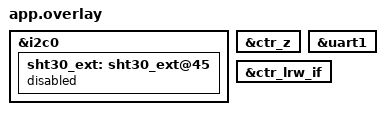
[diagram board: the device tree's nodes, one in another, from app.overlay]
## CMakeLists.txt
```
#
# Copyright (c) 2023 HARDWARIO a.s.
#
# SPDX-License-Identifier: LicenseRef-HARDWARIO-5-Clause
#

cmake_minimum_required(VERSION 3.20.0)

# Supported shields: ctr_lte ctr_x0_a ctr_s2 ctr_z ctr_ds18b20
set(SHIELD ctr_ds18b20 ctr_lte ctr_x0_a ctr_z)

find_package(Zephyr REQUIRED HINTS $ENV{ZEPHYR_BASE})
project(input)

target_sources(app PRIVATE src/app_backup.c)
target_sources(app PRIVATE src/app_cbor.c)
target_sources(app PRIVATE src/app_config.c)
target_sources(app PRIVATE src/app_data.c)
target_sources(app PRIVATE src/app_handler.c)
target_sources(app PRIVATE src/app_init.c)
target_sources(app PRIVATE src/app_power.c)
target_sources(app PRIVATE src/app_send.c)
target_sources(app PRIVATE src/app_sensor.c)
target_sources(app PRIVATE src/app_shell.c)
target_sources(app PRIVATE src/app_work.c)

target_sources(app PRIVATE src/main.c)
```

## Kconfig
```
mainmenu "CHESTER Input"

source "Kconfig.zephyr"
```

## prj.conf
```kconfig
#
# Copyright (c) 2023 HARDWARIO a.s.
#
# SPDX-License-Identifier: LicenseRef-HARDWARIO-5-Clause
#

CONFIG_ADC_SHELL=n
CONFIG_CTR_ACCEL=y
CONFIG_CTR_ADC=y
CONFIG_CTR_BATT=y
CONFIG_CTR_BLE=y
CONFIG_CTR_BUF=y
CONFIG_CTR_BUTTON=y
CONFIG_CTR_DEFAULTS=y
CONFIG_CTR_EDGE=y
CONFIG_CTR_INFO=y
CONFIG_CTR_LED=y
CONFIG_CTR_LOG=y
CONFIG_CTR_LTE_CLKSYNC=y
CONFIG_CTR_RTC=y
CONFIG_CTR_SHELL=y
CONFIG_CTR_THERM=y
CONFIG_CTR_WDOG=y
CONFIG_ENTROPY_GENERATOR=y
CONFIG_TINYCRYPT_SHA256=y
CONFIG_TINYCRYPT=y
CONFIG_ZCBOR_STOP_ON_ERROR=y
CONFIG_ZCBOR=y
```

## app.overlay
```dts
&i2c0 {
	sht30_ext: sht30_ext@45 {
		status = "disabled";
	};
};

&ctr_z {
	status = "okay";
};

&uart1 {
	status = "okay";
};

&ctr_lrw_if {
	status = "okay";
};
```

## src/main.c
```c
/*
 * Copyright (c) 2023 HARDWARIO a.s.
 *
 * SPDX-License-Identifier: LicenseRef-HARDWARIO-5-Clause
 */

#include "app_init.h"

/* CHESTER includes */
#include <chester/ctr_led.h>
#include <chester/ctr_wdog.h>

/* Zephyr includes */
#include <zephyr/kernel.h>
#include <zephyr/logging/log.h>

/* Standard includes */
#include <stdbool.h>

LOG_MODULE_REGISTER(main, LOG_LEVEL_DBG);

extern struct ctr_wdog_channel g_app_wdog_channel;

int main(void)
{
	int ret;

	LOG_INF("Build time: " __DATE__ " " __TIME__);

	ret = app_init();
	if (ret) {
		LOG_ERR("Call `app_init` failed: %d", ret);
		k_oops();
	}

	for (;;) {
		LOG_INF("Alive");

		ret = ctr_wdog_feed(&g_app_wdog_channel);
		if (ret) {
			LOG_ERR("Call `ctr_wdog_feed` failed: %d", ret);
			k_oops();
		}

		ctr_led_set(CTR_LED_CHANNEL_G, true);
		k_sleep(K_MSEC(30));
		ctr_led_set(CTR_LED_CHANNEL_G, false);

		k_sleep(K_SECONDS(5));
	}

	return 0;
}
```

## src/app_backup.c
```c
#include "app_backup.h"
#include "app_data.h"

/* CHESTER includes */
#include <chester/drivers/ctr_z.h>

/* Zephyr includes */
#include <zephyr/device.h>
#include <zephyr/devicetree.h>
#include <zephyr/kernel.h>
#include <zephyr/logging/log.h>

/* Standard includes */
#include <errno.h>
#include <math.h>

LOG_MODULE_REGISTER(app_backup, LOG_LEVEL_DBG);

#if defined(CONFIG_SHIELD_CTR_Z)

int app_backup_sample(void)
{
	int ret;

	static const struct device *dev = DEVICE_DT_GET(DT_NODELABEL(ctr_z));

	if (!device_is_ready(dev)) {
		LOG_ERR("Device not ready");
		ret = -ENODEV;
		goto error;
	}

	struct ctr_z_status status;
	ret = ctr_z_get_status(dev, &status);
	if (ret) {
		LOG_ERR("Call `ctr_z_get_status` failed: %d", ret);
		goto error;
	}

	LOG_INF("DC input connected: %d", status.dc_input_connected);

	uint16_t vdc;
	ret = ctr_z_get_vdc_mv(dev, &vdc);
	if (ret) {
		LOG_ERR("Call `ctr_z_get_vdc_mv` failed: %d", ret);
		goto error;
	}

	LOG_INF("Voltage DC input: %u mV", vdc);

	uint16_t vbat;
	ret = ctr_z_get_vbat_mv(dev, &vbat);
	if (ret) {
		LOG_ERR("Call `ctr_z_get_vbat_mv` failed: %d", ret);
		goto error;
	}

	LOG_INF("Voltage backup battery: %u mV", vbat);

	app_data_lock();
	g_app_data.backup.line_present = status.dc_input_connected;
	g_app_data.backup.line_voltage = vdc / 1000.f;
	g_app_data.backup.battery_voltage = vbat / 1000.f;
	app_data_unlock();

	return 0;

error:
	app_data_lock();
	g_app_data.backup.line_present = false;
	g_app_data.backup.line_voltage = NAN;
	g_app_data.backup.battery_voltage = NAN;
	app_data_unlock();

	return ret;
}

int app_backup_clear(void)
{
	app_data_lock();
	g_app_data.backup.event_count = 0;
	app_data_unlock();

	return 0;
}

#endif /* defined(CONFIG_SHIELD_CTR_Z) */
```

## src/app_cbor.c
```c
/*
 * Copyright (c) 2023 HARDWARIO a.s.
 *
 * SPDX-License-Identifier: LicenseRef-HARDWARIO-5-Clause
 */

#include "app_cbor.h"
#include "app_config.h"
#include "app_data.h"
#include "msg_key.h"

/* CHESTER includes */
#include <chester/ctr_ds18b20.h>
#include <chester/ctr_info.h>
#include <chester/ctr_rtc.h>

/* Zephyr includes */
#include <zephyr/kernel.h>
#include <zephyr/logging/log.h>

#include <zcbor_common.h>
#include <zcbor_encode.h>

/* Standard includes */
#include <errno.h>
#include <math.h>
#include <stdbool.h>
#include <stddef.h>
#include <stdint.h>
#include <stdlib.h>

LOG_MODULE_REGISTER(app_cbor, LOG_LEVEL_DBG);

#if defined(CONFIG_SHIELD_CTR_X0_A)

__unused static void put_sample_mul(zcbor_state_t *zs, struct app_data_aggreg *sample, float mul)
{
	if (isnan(sample->min)) {
		zcbor_nil_put(zs, NULL);
	} else {
		zcbor_int32_put(zs, sample->min * mul);
	}

	if (isnan(sample->max)) {
		zcbor_nil_put(zs, NULL);
	} else {
		zcbor_int32_put(zs, sample->max * mul);
	}

	if (isnan(sample->avg)) {
		zcbor_nil_put(zs, NULL);
	} else {
		zcbor_int32_put(zs, sample->avg * mul);
	}

	if (isnan(sample->mdn)) {
		zcbor_nil_put(zs, NULL);
	} else {
		zcbor_int32_put(zs, sample->mdn * mul);
	}
}

__unused static void put_sample(zcbor_state_t *zs, struct app_data_aggreg *sample)
{
	put_sample_mul(zs, sample, 1.f);
}

#endif /* defined(CONFIG_SHIELD_CTR_X0_A) */

static int encode(zcbor_state_t *zs)
{
	int ret;

	zs->constant_state->stop_on_error = true;

	zcbor_map_start_encode(zs, ZCBOR_VALUE_IS_INDEFINITE_LENGTH);

	zcbor_uint32_put(zs, MSG_KEY_MESSAGE);
	{
		zcbor_map_start_encode(zs, ZCBOR_VALUE_IS_INDEFINITE_LENGTH);

		zcbor_uint32_put(zs, MSG_KEY_VERSION);
		zcbor_uint32_put(zs, 1);

		static uint32_t sequence;
		zcbor_uint32_put(zs, MSG_KEY_SEQUENCE);
		zcbor_uint32_put(zs, sequence++);

		uint64_t timestamp;
		ret = ctr_rtc_get_ts(&timestamp);
		if (ret) {
			LOG_ERR("Call `ctr_rtc_get_ts` failed: %d", ret);
			return ret;
		}

		zcbor_uint32_put(zs, MSG_KEY_TIMESTAMP);
		zcbor_uint64_put(zs, timestamp);

		zcbor_map_end_encode(zs, ZCBOR_VALUE_IS_INDEFINITE_LENGTH);
	}

	zcbor_uint32_put(zs, MSG_KEY_ATTRIBUTE);
	{
		zcbor_map_start_encode(zs, ZCBOR_VALUE_IS_INDEFINITE_LENGTH);

		char *vendor_name;
		ctr_info_get_vendor_name(&vendor_name);

		zcbor_uint32_put(zs, MSG_KEY_VENDOR_NAME);
		zcbor_tstr_put_term(zs, vendor_name, CONFIG_ZCBOR_MAX_STR_LEN);

		char *product_name;
		ctr_info_get_product_name(&product_name);

		zcbor_uint32_put(zs, MSG_KEY_PRODUCT_NAME);
		zcbor_tstr_put_term(zs, product_name, CONFIG_ZCBOR_MAX_STR_LEN);

		char *hw_variant;
		ctr_info_get_hw_variant(&hw_variant);

		zcbor_uint32_put(zs, MSG_KEY_HW_VARIANT);
		zcbor_tstr_put_term(zs, hw_variant, CONFIG_ZCBOR_MAX_STR_LEN);

		char *hw_revision;
		ctr_info_get_hw_revision(&hw_revision);

		zcbor_uint32_put(zs, MSG_KEY_HW_REVISION);
		zcbor_tstr_put_term(zs, hw_revision, CONFIG_ZCBOR_MAX_STR_LEN);

		char *fw_name;
		ctr_info_get_fw_name(&fw_name);

		zcbor_uint32_put(zs, MSG_KEY_FW_NAME);
		zcbor_tstr_put_term(zs, fw_name, CONFIG_ZCBOR_MAX_STR_LEN);

		char *fw_version;
		ctr_info_get_fw_version(&fw_version);

		zcbor_uint32_put(zs, MSG_KEY_FW_VERSION);
		zcbor_tstr_put_term(zs, fw_version, CONFIG_ZCBOR_MAX_STR_LEN);

		char *serial_number;
		ctr_info_get_serial_number(&serial_number);

		zcbor_uint32_put(zs, MSG_KEY_SERIAL_NUMBER);
		zcbor_tstr_put_term(zs, serial_number, CONFIG_ZCBOR_MAX_STR_LEN);

		zcbor_map_end_encode(zs, ZCBOR_VALUE_IS_INDEFINITE_LENGTH);
	}

	zcbor_uint32_put(zs, MSG_KEY_SYSTEM);
	{
		zcbor_map_start_encode(zs, ZCBOR_VALUE_IS_INDEFINITE_LENGTH);

		zcbor_uint32_put(zs, MSG_KEY_UPTIME);
		zcbor_uint64_put(zs, k_uptime_get() / 1000);

		zcbor_uint32_put(zs, MSG_KEY_VOLTAGE_REST);
		if (isnan(g_app_data.system_voltage_rest)) {
			zcbor_nil_put(zs, NULL);
		} else {
			zcbor_uint32_put(zs, g_app_data.system_voltage_rest);
		}

		zcbor_uint32_put(zs, MSG_KEY_VOLTAGE_LOAD);
		if (isnan(g_app_data.system_voltage_load)) {
			zcbor_nil_put(zs, NULL);
		} else {
			zcbor_uint32_put(zs, g_app_data.system_voltage_load);
		}

		zcbor_uint32_put(zs, MSG_KEY_CURRENT_LOAD);
		if (isnan(g_app_data.system_current_load)) {
			zcbor_nil_put(zs, NULL);
		} else {
			zcbor_uint32_put(zs, g_app_data.system_current_load);
		}

		zcbor_map_end_encode(zs, ZCBOR_VALUE_IS_INDEFINITE_LENGTH);
	}

#if defined(CONFIG_SHIELD_CTR_Z)
	zcbor_uint32_put(zs, MSG_KEY_BACKUP);
	{
		zcbor_map_start_encode(zs, ZCBOR_VALUE_IS_INDEFINITE_LENGTH);

		zcbor_uint32_put(zs, MSG_KEY_LINE_VOLTAGE);
		if (isnan(g_app_data.backup.line_voltage)) {
			zcbor_nil_put(zs, NULL);
		} else {
			zcbor_int32_put(zs, g_app_data.backup.line_voltage * 1000.f);
		}

		zcbor_uint32_put(zs, MSG_KEY_BATT_VOLTAGE);
		if (isnan(g_app_data.backup.battery_voltage)) {
			zcbor_nil_put(zs, NULL);
		} else {
			zcbor_int32_put(zs, g_app_data.backup.battery_voltage * 1000.f);
		}

		zcbor_uint32_put(zs, MSG_KEY_BACKUP_STATE);
		zcbor_uint32_put(zs, g_app_data.backup.line_present ? 1 : 0);

		if (g_app_data.backup.event_count) {
			int64_t timestamp_abs = g_app_data.backup.events[0].timestamp;

			zcbor_uint32_put(zs, MSG_KEY_BACKUP_EVENTS);
			{
				zcbor_list_start_encode(zs, ZCBOR_VALUE_IS_INDEFINITE_LENGTH);

				/* TSO absolute timestamp */
				zcbor_int64_put(zs, timestamp_abs);

				for (int i = 0; i < g_app_data.backup.event_count; i++) {
					/* TSO offset timestamp */
					zcbor_int64_put(zs, g_app_data.backup.events[i].timestamp -
								    timestamp_abs);
					zcbor_uint32_put(
						zs, g_app_data.backup.events[i].connected ? 1 : 0);
				}

				zcbor_list_end_encode(zs, ZCBOR_VALUE_IS_INDEFINITE_LENGTH);
			}
		} else {
			zcbor_uint32_put(zs, MSG_KEY_BACKUP_EVENTS);
			{
				zcbor_list_start_encode(zs, ZCBOR_VALUE_IS_INDEFINITE_LENGTH);
				zcbor_list_end_encode(zs, ZCBOR_VALUE_IS_INDEFINITE_LENGTH);
			}
		}

		zcbor_map_end_encode(zs, ZCBOR_VALUE_IS_INDEFINITE_LENGTH);
	}
#endif /* defined(CONFIG_SHIELD_CTR_Z) */

	zcbor_uint32_put(zs, MSG_KEY_NETWORK);
	{
		zcbor_map_start_encode(zs, ZCBOR_VALUE_IS_INDEFINITE_LENGTH);

		uint64_t imei;
		ret = ctr_lte_get_imei(&imei);
		if (ret) {
			LOG_ERR("Call `ctr_lte_get_imei` failed: %d", ret);
			return ret;
		}

		zcbor_uint32_put(zs, MSG_KEY_IMEI);
		zcbor_uint64_put(zs, imei);

		uint64_t imsi;
		ret = ctr_lte_get_imsi(&imsi);
		if (ret) {
			LOG_ERR("Call `ctr_lte_get_imsi` failed: %d", ret);
			return ret;
		}

		zcbor_uint32_put(zs, MSG_KEY_IMSI);
		zcbor_uint64_put(zs, imsi);

		zcbor_uint32_put(zs, MSG_KEY_PARAMETER);
		{
			zcbor_map_start_encode(zs, ZCBOR_VALUE_IS_INDEFINITE_LENGTH);

			k_mutex_lock(&g_app_data_lte_eval_mut, K_FOREVER);

			zcbor_uint32_put(zs, MSG_KEY_EEST);
			if (g_app_data_lte_eval_valid) {
				zcbor_int32_put(zs, g_app_data_lte_eval.eest);
			} else {
				zcbor_nil_put(zs, NULL);
			}

			zcbor_uint32_put(zs, MSG_KEY_ECL);
			if (g_app_data_lte_eval_valid) {
				zcbor_int32_put(zs, g_app_data_lte_eval.ecl);
			} else {
				zcbor_nil_put(zs, NULL);
			}

			zcbor_uint32_put(zs, MSG_KEY_RSRP);
			if (g_app_data_lte_eval_valid) {
				zcbor_int32_put(zs, g_app_data_lte_eval.rsrp);
			} else {
				zcbor_nil_put(zs, NULL);
			}

			zcbor_uint32_put(zs, MSG_KEY_RSRQ);
			if (g_app_data_lte_eval_valid) {
				zcbor_int32_put(zs, g_app_data_lte_eval.rsrq);
			} else {
				zcbor_nil_put(zs, NULL);
			}

			zcbor_uint32_put(zs, MSG_KEY_SNR);
			if (g_app_data_lte_eval_valid) {
				zcbor_int32_put(zs, g_app_data_lte_eval.snr);
			} else {
				zcbor_nil_put(zs, NULL);
			}

			zcbor_uint32_put(zs, MSG_KEY_PLMN);
			if (g_app_data_lte_eval_valid) {
				zcbor_int32_put(zs, g_app_data_lte_eval.plmn);
			} else {
				zcbor_nil_put(zs, NULL);
			}

			zcbor_uint32_put(zs, MSG_KEY_CID);
			if (g_app_data_lte_eval_valid) {
				zcbor_int32_put(zs, g_app_data_lte_eval.cid);
			} else {
				zcbor_nil_put(zs, NULL);
			}

			zcbor_uint32_put(zs, MSG_KEY_BAND);
			if (g_app_data_lte_eval_valid) {
				zcbor_int32_put(zs, g_app_data_lte_eval.band);
			} else {
				zcbor_nil_put(zs, NULL);
			}

			zcbor_uint32_put(zs, MSG_KEY_EARFCN);
			if (g_app_data_lte_eval_valid) {
				zcbor_int32_put(zs, g_app_data_lte_eval.earfcn);
			} else {
				zcbor_nil_put(zs, NULL);
			}

			g_app_data_lte_eval_valid = false;

			k_mutex_unlock(&g_app_data_lte_eval_mut);

			zcbor_map_end_encode(zs, ZCBOR_VALUE_IS_INDEFINITE_LENGTH);
		}

		zcbor_map_end_encode(zs, ZCBOR_VALUE_IS_INDEFINITE_LENGTH);
	}

	zcbor_uint32_put(zs, MSG_KEY_THERMOMETER);
	{
		zcbor_map_start_encode(zs, ZCBOR_VALUE_IS_INDEFINITE_LENGTH);

		zcbor_uint32_put(zs, MSG_KEY_TEMPERATURE);
		if (isnan(g_app_data.therm_temperature)) {
			zcbor_nil_put(zs, NULL);
		} else {
			zcbor_int32_put(zs, g_app_data.therm_temperature * 100.f);
		}

		zcbor_map_end_encode(zs, ZCBOR_VALUE_IS_INDEFINITE_LENGTH);
	}

	zcbor_uint32_put(zs, MSG_KEY_ACCELEROMETER);
	{
		zcbor_map_start_encode(zs, ZCBOR_VALUE_IS_INDEFINITE_LENGTH);

		zcbor_uint32_put(zs, MSG_KEY_ACCELERATION_X);
		if (isnan(g_app_data.accel_acceleration_x)) {
			zcbor_nil_put(zs, NULL);
		} else {
			zcbor_int32_put(zs, g_app_data.accel_acceleration_x * 1000.f);
		}

		zcbor_uint32_put(zs, MSG_KEY_ACCELERATION_Y);
		if (isnan(g_app_data.accel_acceleration_y)) {
			zcbor_nil_put(zs, NULL);
		} else {
			zcbor_int32_put(zs, g_app_data.accel_acceleration_y * 1000.f);
		}

		zcbor_uint32_put(zs, MSG_KEY_ACCELERATION_Z);
		if (isnan(g_app_data.accel_acceleration_z)) {
			zcbor_nil_put(zs, NULL);
		} else {
			zcbor_int32_put(zs, g_app_data.accel_acceleration_z * 1000.f);
		}

		zcbor_uint32_put(zs, MSG_KEY_ORIENTATION);
		if (g_app_data.accel_orientation == INT_MAX) {
			zcbor_nil_put(zs, NULL);
		} else {
			zcbor_uint32_put(zs, g_app_data.accel_orientation);
		}

		zcbor_map_end_encode(zs, ZCBOR_VALUE_IS_INDEFINITE_LENGTH);
	}

#if defined(CONFIG_SHIELD_CTR_X0_A)
	zcbor_uint32_put(zs, MSG_KEY_TRIGGER);
	{
		zcbor_map_start_encode(zs, ZCBOR_VALUE_IS_INDEFINITE_LENGTH);

		zcbor_uint32_put(zs, MSG_KEY_TRIGGER_STATE);
		zcbor_uint32_put(zs, g_app_data.trigger.trigger_active ? 1 : 0);

		if (g_app_data.trigger.event_count) {

			int64_t timestamp_abs = g_app_data.trigger.events[0].timestamp;

			zcbor_uint32_put(zs, MSG_KEY_TRIGGER_EVENTS);
			{
				zcbor_list_start_encode(zs, ZCBOR_VALUE_IS_INDEFINITE_LENGTH);

				/* TSO absolute timestamp */
				zcbor_int64_put(zs, timestamp_abs);

				for (int i = 0; i < g_app_data.trigger.event_count; i++) {
					/* TSO offset timestamp */
					zcbor_int64_put(zs, g_app_data.trigger.events[i].timestamp -
								    timestamp_abs);
					zcbor_uint32_put(
						zs, g_app_data.trigger.events[i].is_active ? 1 : 0);
				}

				zcbor_list_end_encode(zs, ZCBOR_VALUE_IS_INDEFINITE_LENGTH);
			}
		} else {
			zcbor_uint32_put(zs, MSG_KEY_TRIGGER_EVENTS);
			{
				zcbor_list_start_encode(zs, ZCBOR_VALUE_IS_INDEFINITE_LENGTH);
				zcbor_list_end_encode(zs, ZCBOR_VALUE_IS_INDEFINITE_LENGTH);
			}
		}
		zcbor_map_end_encode(zs, ZCBOR_VALUE_IS_INDEFINITE_LENGTH);
	}

	zcbor_uint32_put(zs, MSG_KEY_COUNTER);
	{
		zcbor_map_start_encode(zs, ZCBOR_VALUE_IS_INDEFINITE_LENGTH);

		zcbor_uint32_put(zs, MSG_KEY_VALUE);
		zcbor_uint64_put(zs, g_app_data.counter.value);

		zcbor_uint32_put(zs, MSG_KEY_DELTA);
		zcbor_uint64_put(zs, g_app_data.counter.delta);

		g_app_data.counter.delta = 0;

		zcbor_uint32_put(zs, MSG_KEY_MEASUREMENTS_VAL);
		{
			zcbor_list_start_encode(zs, ZCBOR_VALUE_IS_INDEFINITE_LENGTH);

			zcbor_uint64_put(zs, g_app_data.counter.timestamp);
			zcbor_uint32_put(zs, g_app_config.counter_interval_aggreg);

			for (int i = 0; i < g_app_data.counter.measurement_count; i++) {
				zcbor_uint64_put(zs, g_app_data.counter.measurements[i].value);
			}

			zcbor_list_end_encode(zs, ZCBOR_VALUE_IS_INDEFINITE_LENGTH);
		}
		zcbor_map_end_encode(zs, ZCBOR_VALUE_IS_INDEFINITE_LENGTH);
	}

	zcbor_uint32_put(zs, MSG_KEY_VOLTAGE);
	{
		zcbor_map_start_encode(zs, ZCBOR_VALUE_IS_INDEFINITE_LENGTH);

		zcbor_uint32_put(zs, MSG_KEY_MEASUREMENTS_DIV);
		{
			zcbor_list_start_encode(zs, ZCBOR_VALUE_IS_INDEFINITE_LENGTH);

			zcbor_uint64_put(zs, g_app_data.voltage.timestamp);
			zcbor_uint32_put(zs, g_app_config.analog_interval_aggreg);

			for (int i = 0; i < g_app_data.voltage.measurement_count; i++) {
				put_sample_mul(zs, &g_app_data.voltage.measurements[i], 100.f);
			}

			zcbor_list_end_encode(zs, ZCBOR_VALUE_IS_INDEFINITE_LENGTH);
		}
		zcbor_map_end_encode(zs, ZCBOR_VALUE_IS_INDEFINITE_LENGTH);
	}

	zcbor_uint32_put(zs, MSG_KEY_CURRENT);
	{
		zcbor_map_start_encode(zs, ZCBOR_VALUE_IS_INDEFINITE_LENGTH);

		zcbor_uint32_put(zs, MSG_KEY_MEASUREMENTS_DIV);
		{
			zcbor_list_start_encode(zs, ZCBOR_VALUE_IS_INDEFINITE_LENGTH);

			zcbor_uint64_put(zs, g_app_data.current.timestamp);
			zcbor_uint32_put(zs, g_app_config.analog_interval_aggreg);

			for (int i = 0; i < g_app_data.current.measurement_count; i++) {
				put_sample_mul(zs, &g_app_data.current.measurements[i], 100.f);
			}

			zcbor_list_end_encode(zs, ZCBOR_VALUE_IS_INDEFINITE_LENGTH);
		}
		zcbor_map_end_encode(zs, ZCBOR_VALUE_IS_INDEFINITE_LENGTH);
	}
#endif /* defined(CONFIG_SHIELD_CTR_X0_A) */

#if defined(CONFIG_SHIELD_CTR_S2)
	zcbor_uint32_put(zs, MSG_KEY_HYGROMETER);
	{
		zcbor_map_start_encode(zs, ZCBOR_VALUE_IS_INDEFINITE_LENGTH);

		zcbor_uint32_put(zs, MSG_KEY_TEMPERATURE);
		{
			zcbor_map_start_encode(zs, ZCBOR_VALUE_IS_INDEFINITE_LENGTH);

			zcbor_uint32_put(zs, MSG_KEY_MEASUREMENTS_DIV);
			{
				zcbor_list_start_encode(zs, ZCBOR_VALUE_IS_INDEFINITE_LENGTH);

				zcbor_uint64_put(zs, g_app_data.hygro.timestamp);
				zcbor_uint32_put(zs, g_app_config.hygro_interval_aggreg);

				for (int i = 0; i < g_app_data.hygro.measurement_count; i++) {
					put_sample_mul(
						zs, &g_app_data.hygro.measurements[i].temperature,
						100.f);
				}

				zcbor_list_end_encode(zs, ZCBOR_VALUE_IS_INDEFINITE_LENGTH);
			}
			zcbor_map_end_encode(zs, ZCBOR_VALUE_IS_INDEFINITE_LENGTH);
		}

		zcbor_uint32_put(zs, MSG_KEY_HUMIDITY);
		{
			zcbor_map_start_encode(zs, ZCBOR_VALUE_IS_INDEFINITE_LENGTH);

			zcbor_uint32_put(zs, MSG_KEY_MEASUREMENTS_DIV);
			{
				zcbor_list_start_encode(zs, ZCBOR_VALUE_IS_INDEFINITE_LENGTH);

				zcbor_uint64_put(zs, g_app_data.hygro.timestamp);
				zcbor_uint32_put(zs, g_app_config.hygro_interval_aggreg);

				for (int i = 0; i < g_app_data.hygro.measurement_count; i++) {
					put_sample_mul(zs,
						       &g_app_data.hygro.measurements[i].humidity,
						       100.f);
				}

				zcbor_list_end_encode(zs, ZCBOR_VALUE_IS_INDEFINITE_LENGTH);
			}
			zcbor_map_end_encode(zs, ZCBOR_VALUE_IS_INDEFINITE_LENGTH);
		}

		zcbor_map_end_encode(zs, ZCBOR_VALUE_IS_INDEFINITE_LENGTH);
	}
#endif /* defined(CONFIG_SHIELD_CTR_S2) */

#if defined(CONFIG_SHIELD_CTR_DS18B20)
	if (ctr_ds18b20_get_count()) {
		zcbor_uint32_put(zs, MSG_KEY_W1_THERMOMETERS);
		{
			zcbor_list_start_encode(zs, ZCBOR_VALUE_IS_INDEFINITE_LENGTH);
			for (int i = 0; i < APP_DATA_W1_THERM_COUNT; i++) {
				struct app_data_w1_therm_sensor *sensor =
					&g_app_data.w1_therm.sensor[i];

				if (!sensor->serial_number) {
					continue;
				}

				zcbor_map_start_encode(zs, ZCBOR_VALUE_IS_INDEFINITE_LENGTH);

				zcbor_uint32_put(zs, MSG_KEY_SERIAL_NUMBER);
				zcbor_uint64_put(zs, sensor->serial_number);

				zcbor_uint32_put(zs, MSG_KEY_MEASUREMENTS_DIV);
				{
					zcbor_list_start_encode(zs,
								ZCBOR_VALUE_IS_INDEFINITE_LENGTH);

					zcbor_uint64_put(zs, g_app_data.w1_therm.timestamp);
					zcbor_uint32_put(zs, g_app_config.w1_therm_interval_aggreg);

					for (int j = 0; j < sensor->measurement_count; j++) {
						put_sample_mul(zs,
							       &sensor->measurements[j].temperature,
							       100.f);
					}

					zcbor_list_end_encode(zs, ZCBOR_VALUE_IS_INDEFINITE_LENGTH);
				}

				zcbor_map_end_encode(zs, ZCBOR_VALUE_IS_INDEFINITE_LENGTH);
			}
			zcbor_list_end_encode(zs, ZCBOR_VALUE_IS_INDEFINITE_LENGTH);
		}
	}
#endif /* defined(CONFIG_SHIELD_CTR_DS18B20) */

	zcbor_map_end_encode(zs, ZCBOR_VALUE_IS_INDEFINITE_LENGTH);

	if (!zcbor_check_error(zs)) {
		LOG_ERR("Encoding failed: %d", zcbor_pop_error(zs));
		return -EFAULT;
	}

	return 0;
}

int app_cbor_encode(zcbor_state_t *zs)
{
	int ret;

	app_data_lock();

	ret = encode(zs);
	if (ret) {
		LOG_ERR("Call `encode` failed: %d", ret);
		app_data_unlock();
		return ret;
	}

	app_data_unlock();

	return 0;
}
```

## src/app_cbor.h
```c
#ifndef APP_CBOR_H_
#define APP_CBOR_H_

/* Zephyr includes */
#include <zephyr/zephyr.h>

#include <zcbor_common.h>

#ifdef __cplusplus
extern "C" {
#endif

int app_cbor_encode(zcbor_state_t *zs);

#ifdef __cplusplus
}
#endif

#endif /* APP_CBOR_H_ */
```

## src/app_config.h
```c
/*
 * Copyright (c) 2023 HARDWARIO a.s.
 *
 * SPDX-License-Identifier: LicenseRef-HARDWARIO-5-Clause
 */

#ifndef APP_CONFIG_H_
#define APP_CONFIG_H_

/* Zephyr includes */
#include <zephyr/shell/shell.h>

/* Standard includes */
#include <stddef.h>

#ifdef __cplusplus
extern "C" {
#endif

#if defined(CONFIG_SHIELD_CTR_X0_A)
enum app_config_input_type {
	APP_CONFIG_INPUT_TYPE_NPN = 0,
	APP_CONFIG_INPUT_TYPE_PNP = 1,
};
#endif /* defined(CONFIG_SHIELD_CTR_X0_A) */

struct app_config {
	int interval_report;

#if defined(CONFIG_SHIELD_CTR_X0_A) || defined(CONFIG_SHIELD_CTR_Z)
	int event_report_delay;
	int event_report_rate;
#endif /* defined(CONFIG_SHIELD_CTR_X0_A) || defined(CONFIG_SHIELD_CTR_Z) */

#if defined(CONFIG_SHIELD_CTR_Z)
	bool backup_report_connected;
	bool backup_report_disconnected;
#endif /* defined(CONFIG_SHIELD_CTR_Z) */

#if defined(CONFIG_SHIELD_CTR_X0_A)
	enum app_config_input_type trigger_input_type;
	int trigger_duration_active;
	int trigger_duration_inactive;
	int trigger_cooldown_time;
	bool trigger_report_active;
	bool trigger_report_inactive;

	int counter_interval_aggreg;
	enum app_config_input_type counter_input_type;
	int counter_duration_active;
	int counter_duration_inactive;
	int counter_cooldown_time;
	int analog_interval_sample;
	int analog_interval_aggreg;
#endif /* defined(CONFIG_SHIELD_CTR_X0_A) */

#if defined(CONFIG_SHIELD_CTR_S2)
	int hygro_interval_sample;
	int hygro_interval_aggreg;
#endif /* defined(CONFIG_SHIELD_CTR_S2) */
};

extern struct app_config g_app_config;

int app_config_cmd_config_show(const struct shell *shell, size_t argc, char **argv);
int app_config_cmd_config_interval_report(const struct shell *shell, size_t argc, char **argv);

#if defined(CONFIG_SHIELD_CTR_X0_A) || defined(CONFIG_SHIELD_CTR_Z)
int app_config_cmd_config_event_report_delay(const struct shell *shell, size_t argc, char **argv);
int app_config_cmd_config_event_report_rate(const struct shell *shell, size_t argc, char **argv);
#endif /* defined(CONFIG_SHIELD_CTR_X0_A) || defined(CONFIG_SHIELD_CTR_Z) */

#if defined(CONFIG_SHIELD_CTR_Z)
int app_config_cmd_config_backup_report_connected(const struct shell *shell, size_t argc,
						  char **argv);
int app_config_cmd_config_backup_report_disconnected(const struct shell *shell, size_t argc,
						     char **argv);
#endif /* defined(CONFIG_SHIELD_CTR_Z) */

#if defined(CONFIG_SHIELD_CTR_X0_A)
int app_config_cmd_config_trigger_input_type(const struct shell *shell, size_t argc, char **argv);
int app_config_cmd_config_trigger_duration_active(const struct shell *shell, size_t argc,
						  char **argv);
int app_config_cmd_config_trigger_duration_inactive(const struct shell *shell, size_t argc,
						    char **argv);
int app_config_cmd_config_trigger_cooldown_time(const struct shell *shell, size_t argc,
						char **argv);
int app_config_cmd_config_trigger_report_active(const struct shell *shell, size_t argc,
						char **argv);
int app_config_cmd_config_trigger_report_inactive(const struct shell *shell, size_t argc,
						  char **argv);

int app_config_cmd_config_counter_interval_aggreg(const struct shell *shell, size_t argc,
						  char **argv);
int app_config_cmd_config_counter_input_type(const struct shell *shell, size_t argc, char **argv);
int app_config_cmd_config_counter_duration_active(const struct shell *shell, size_t argc,
						  char **argv);
int app_config_cmd_config_counter_duration_inactive(const struct shell *shell, size_t argc,
						    char **argv);
int app_config_cmd_config_counter_cooldown_time(const struct shell *shell, size_t argc,
						char **argv);
int app_config_cmd_config_analog_interval_sample(const struct shell *shell, size_t argc,
						 char **argv);
int app_config_cmd_config_analog_interval_aggreg(const struct shell *shell, size_t argc,
						 char **argv);
#endif /* defined(CONFIG_SHIELD_CTR_X0_A) */

#if defined(CONFIG_SHIELD_CTR_S2)
int app_config_cmd_config_hygro_interval_sample(const struct shell *shell, size_t argc,
						char **argv);
int app_config_cmd_config_hygro_interval_aggreg(const struct shell *shell, size_t argc,
						char **argv);
#endif /* defined(CONFIG_SHIELD_CTR_S2) */
#ifdef __cplusplus
}
#endif

#endif /* APP_CONFIG_H_ */
```

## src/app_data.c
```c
/*
 * Copyright (c) 2023 HARDWARIO a.s.
 *
 * SPDX-License-Identifier: LicenseRef-HARDWARIO-5-Clause
 */

#include "app_data.h"
#include "msg_key.h"

/* CHESTER includes */
#include <chester/ctr_lte.h>

/* Zephyr includes */
#include <zephyr/kernel.h>

/* Standard includes */
#include <limits.h>
#include <math.h>

struct app_data g_app_data = {
	.system_voltage_rest = NAN,
	.system_voltage_load = NAN,
	.system_current_load = NAN,
	.accel_acceleration_x = NAN,
	.accel_acceleration_y = NAN,
	.accel_acceleration_z = NAN,
	.accel_orientation = INT_MAX,
	.therm_temperature = NAN,
};

static K_MUTEX_DEFINE(m_lock);

void app_data_lock(void)
{
	k_mutex_lock(&m_lock, K_FOREVER);
}

void app_data_unlock(void)
{
	k_mutex_unlock(&m_lock);
}

K_MUTEX_DEFINE(g_app_data_lte_eval_mut);
bool g_app_data_lte_eval_valid;
struct ctr_lte_eval g_app_data_lte_eval;
```

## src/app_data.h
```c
/*
 * Copyright (c) 2023 HARDWARIO a.s.
 *
 * SPDX-License-Identifier: LicenseRef-HARDWARIO-5-Clause
 */

#ifndef APP_DATA_H_
#define APP_DATA_H_

/* CHESTER includes */
#include <chester/ctr_edge.h>
#include <chester/ctr_lte.h>

/* Standard includes */
#include <stdbool.h>
#include <stdint.h>

/* TODO Delete */
#include <zephyr/kernel.h>

#define APP_DATA_ANALOG_MAX_SAMPLES	 32
#define APP_DATA_ANALOG_MAX_MEASUREMENTS 32

#define APP_DATA_COUNTER_MAX_MEASUREMENTS 32

#define APP_DATA_MAX_TRIGGER_EVENTS 32
#define APP_DATA_MAX_BACKUP_EVENTS  32

#define APP_DATA_HYGRO_MAX_SAMPLES	32
#define APP_DATA_HYGRO_MAX_MEASUREMENTS 32

#if defined(CONFIG_SHIELD_CTR_DS18B20)
#define APP_DATA_W1_THERM_COUNT	      10
#define APP_DATA_W1_THERM_MAX_SAMPLES 128
#define APP_DATA_W1_THERM_MAX_MEASUREMENTS  32
#endif /* defined(CONFIG_SHIELD_CTR_DS18B20) */

#ifdef __cplusplus
extern "C" {
#endif

struct app_data_aggreg {
	float min;
	float max;
	float avg;
	float mdn;
};

#if defined(CONFIG_SHIELD_CTR_Z)

struct app_data_backup_event {
	int64_t timestamp;
	bool connected;
};

struct app_data_backup {
	float line_voltage;
	float battery_voltage;
	bool line_present;
	int event_count;
	struct app_data_backup_event events[APP_DATA_MAX_BACKUP_EVENTS];
};

#endif /* defined(CONFIG_SHIELD_CTR_Z) */

#if defined(CONFIG_SHIELD_CTR_X0_A)

struct app_data_trigger_event {
	int64_t timestamp;
	bool is_active;
};

struct app_data_trigger {
	bool trigger_active;
	int event_count;
	struct app_data_trigger_event events[APP_DATA_MAX_TRIGGER_EVENTS];
};

struct app_data_counter_measurement {
	uint64_t value;
};

struct app_data_counter {
	int64_t timestamp;
	uint64_t value;
	uint64_t delta;
	int measurement_count;
	struct app_data_counter_measurement measurements[APP_DATA_COUNTER_MAX_MEASUREMENTS];
};

struct app_data_analog {
	int64_t timestamp;
	int sample_count;
	float samples[APP_DATA_ANALOG_MAX_SAMPLES];
	int measurement_count;
	struct app_data_aggreg measurements[APP_DATA_ANALOG_MAX_MEASUREMENTS];
};

#endif /* defined(CONFIG_SHIELD_CTR_X0_A) */

#if defined(CONFIG_SHIELD_CTR_S2)

struct app_data_hygro_measurement {
	struct app_data_aggreg temperature;
	struct app_data_aggreg humidity;
};

struct app_data_hygro {
	int64_t timestamp;
	int sample_count;
	float samples_temperature[APP_DATA_HYGRO_MAX_SAMPLES];
	float samples_humidity[APP_DATA_HYGRO_MAX_SAMPLES];
	int measurement_count;
	struct app_data_hygro_measurement measurements[APP_DATA_HYGRO_MAX_MEASUREMENTS];
};

#endif /* defined(CONFIG_SHIELD_CTR_S2) */

#if defined(CONFIG_SHIELD_CTR_DS18B20)
struct app_data_w1_therm_measurement {
	struct app_data_aggreg temperature;
};

struct app_data_w1_therm_sensor {
	uint64_t serial_number;

	float last_sample_temperature;

	int sample_count;
	float samples_temperature[APP_DATA_W1_THERM_MAX_SAMPLES];

	int measurement_count;
	struct app_data_w1_therm_measurement measurements[APP_DATA_W1_THERM_MAX_MEASUREMENTS];
};

struct app_data_w1_therm {
	struct app_data_w1_therm_sensor sensor[APP_DATA_W1_THERM_COUNT];

	int64_t timestamp;
	atomic_t sample;
	atomic_t aggreg;
};
#endif /* defined(CONFIG_SHIELD_CTR_DS18B20) */

struct app_data {
	float system_voltage_rest;
	float system_voltage_load;
	float system_current_load;
	float therm_temperature;
	float accel_acceleration_x;
	float accel_acceleration_y;
	float accel_acceleration_z;
	int accel_orientation;

#if defined(CONFIG_SHIELD_CTR_Z)
	struct app_data_backup backup;
#endif /* defined(CONFIG_SHIELD_CTR_Z) */

#if defined(CONFIG_SHIELD_CTR_X0_A)
	struct app_data_counter counter;
	struct app_data_trigger trigger;
	struct app_data_analog voltage;
	struct app_data_analog current;
#endif /* defined(CONFIG_SHIELD_CTR_X0_A) */

#if defined(CONFIG_SHIELD_CTR_S2)
	struct app_data_hygro hygro;
#endif /* defined(CONFIG_SHIELD_CTR_S2) */

#if defined(CONFIG_SHIELD_CTR_DS18B20)
	struct app_data_w1_therm w1_therm;
#endif /* defined(CONFIG_SHIELD_CTR_DS18B20) */
};

extern struct app_data g_app_data;

/* TODO Delete */
extern struct k_mutex g_app_data_lte_eval_mut;
extern bool g_app_data_lte_eval_valid;
extern struct ctr_lte_eval g_app_data_lte_eval;

void app_data_lock(void);
void app_data_unlock(void);

#ifdef __cplusplus
}
#endif

#endif /* APP_DATA_H_ */
```

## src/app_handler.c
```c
/*
 * Copyright (c) 2023 HARDWARIO a.s.
 *
 * SPDX-License-Identifier: LicenseRef-HARDWARIO-5-Clause
 */

#include "app_config.h"
#include "app_data.h"
#include "app_handler.h"
#include "app_init.h"
#include "app_work.h"

/* CHESTER includes */
#include <chester/ctr_lte.h>
#include <chester/ctr_rtc.h>
#include <chester/drivers/ctr_z.h>

/* Zephyr includes */
#include <zephyr/kernel.h>
#include <zephyr/logging/log.h>

/* Standard includes */
#include <inttypes.h>
#include <math.h>
#include <stdbool.h>
#include <stddef.h>

LOG_MODULE_REGISTER(app_handler, LOG_LEVEL_DBG);

static atomic_t m_report_rate_hourly_counter = 0;
static atomic_t m_report_rate_timer_is_active = false;
static atomic_t m_report_delay_timer_is_active = false;

#if defined(CONFIG_SHIELD_CTR_LTE)

static void start(void)
{
	int ret;

	ret = ctr_lte_start(NULL);
	if (ret) {
		LOG_ERR("Call `ctr_lte_start` failed: %d", ret);
		k_oops();
	}
}

static void attach(void)
{
	int ret;

	ret = ctr_lte_attach(NULL);
	if (ret) {
		LOG_ERR("Call `ctr_lte_attach` failed: %d", ret);
		k_oops();
	}
}

void app_handler_lte(enum ctr_lte_event event, union ctr_lte_event_data *data, void *param)
{
	switch (event) {
	case CTR_LTE_EVENT_FAILURE:
		LOG_ERR("Event `CTR_LTE_EVENT_FAILURE`");
		start();
		break;

	case CTR_LTE_EVENT_START_OK:
		LOG_INF("Event `CTR_LTE_EVENT_START_OK`");
		attach();
		break;

	case CTR_LTE_EVENT_START_ERR:
		LOG_ERR("Event `CTR_LTE_EVENT_START_ERR`");
		start();
		break;

	case CTR_LTE_EVENT_ATTACH_OK:
		LOG_INF("Event `CTR_LTE_EVENT_ATTACH_OK`");
		k_sem_give(&g_app_init_sem);
		break;

	case CTR_LTE_EVENT_ATTACH_ERR:
		LOG_ERR("Event `CTR_LTE_EVENT_ATTACH_ERR`");
		start();
		break;

	case CTR_LTE_EVENT_DETACH_OK:
		LOG_INF("Event `CTR_LTE_EVENT_DETACH_OK`");
		break;

	case CTR_LTE_EVENT_DETACH_ERR:
		LOG_ERR("Event `CTR_LTE_EVENT_DETACH_ERR`");
		start();
		break;

	case CTR_LTE_EVENT_EVAL_OK:
		LOG_INF("Event `CTR_LTE_EVENT_EVAL_OK`");

		struct ctr_lte_eval *eval = &data->eval_ok.eval;

		LOG_DBG("EEST: %d", eval->eest);
		LOG_DBG("ECL: %d", eval->ecl);
		LOG_DBG("RSRP: %d", eval->rsrp);
		LOG_DBG("RSRQ: %d", eval->rsrq);
		LOG_DBG("SNR: %d", eval->snr);
		LOG_DBG("PLMN: %d", eval->plmn);
		LOG_DBG("CID: %d", eval->cid);
		LOG_DBG("BAND: %d", eval->band);
		LOG_DBG("EARFCN: %d", eval->earfcn);

		k_mutex_lock(&g_app_data_lte_eval_mut, K_FOREVER);
		memcpy(&g_app_data_lte_eval, &data->eval_ok.eval, sizeof(g_app_data_lte_eval));
		g_app_data_lte_eval_valid = true;
		k_mutex_unlock(&g_app_data_lte_eval_mut);

		break;

	case CTR_LTE_EVENT_EVAL_ERR:
		LOG_ERR("Event `CTR_LTE_EVENT_EVAL_ERR`");

		k_mutex_lock(&g_app_data_lte_eval_mut, K_FOREVER);
		g_app_data_lte_eval_valid = false;
		k_mutex_unlock(&g_app_data_lte_eval_mut);

		break;

	case CTR_LTE_EVENT_SEND_OK:
		LOG_INF("Event `CTR_LTE_EVENT_SEND_OK`");
		break;

	case CTR_LTE_EVENT_SEND_ERR:
		LOG_ERR("Event `CTR_LTE_EVENT_SEND_ERR`");
		start();
		break;

	default:
		LOG_WRN("Unknown event: %d", event);
		return;
	}
}

#endif /* defined(CONFIG_SHIELD_CTR_LTE) */

static void report_delay_timer_handler(struct k_timer *timer)
{
	app_work_send();
	atomic_inc(&m_report_rate_hourly_counter);
	atomic_set(&m_report_delay_timer_is_active, false);
}

static K_TIMER_DEFINE(m_report_delay_timer, report_delay_timer_handler, NULL);

static void report_rate_timer_handler(struct k_timer *timer)
{
	atomic_set(&m_report_rate_hourly_counter, 0);
	atomic_set(&m_report_rate_timer_is_active, false);
}

static K_TIMER_DEFINE(m_report_rate_timer, report_rate_timer_handler, NULL);

#if defined(CONFIG_SHIELD_CTR_X0_A) || defined(CONFIG_SHIELD_CTR_Z)

static void send_with_rate_limit(void)
{
	if (!atomic_get(&m_report_rate_timer_is_active)) {
		k_timer_start(&m_report_rate_timer, K_HOURS(1), K_NO_WAIT);
		atomic_set(&m_report_rate_timer_is_active, true);
	}

	LOG_INF("Hourly counter state: %d/%d", (int)atomic_get(&m_report_rate_hourly_counter),
		g_app_config.event_report_rate);

	if (atomic_get(&m_report_rate_hourly_counter) <= g_app_config.event_report_rate) {
		if (!atomic_get(&m_report_delay_timer_is_active)) {
			LOG_INF("Starting delay timer");
			k_timer_start(&m_report_delay_timer,
				      K_SECONDS(g_app_config.event_report_delay), K_NO_WAIT);
			atomic_set(&m_report_delay_timer_is_active, true);
		} else {
			LOG_INF("Delay timer already running");
		}
	} else {
		LOG_WRN("Hourly counter exceeded");
	}
}

#endif

#if defined(CONFIG_SHIELD_CTR_X0_A)

void app_handler_edge_trigger_callback(struct ctr_edge *edge, enum ctr_edge_event edge_event,
				       void *user_data)
{
	int ret;

	struct app_data_trigger *trigger = &g_app_data.trigger;

	app_data_lock();

	if (trigger->event_count < APP_DATA_MAX_TRIGGER_EVENTS) {
		struct app_data_trigger_event *event = &trigger->events[trigger->event_count];

		ret = ctr_rtc_get_ts(&event->timestamp);
		if (ret) {
			LOG_ERR("Call `ctr_rtc_get_ts` failed: %d", ret);
			app_data_unlock();
			return;
		}

		event->is_active = edge_event == CTR_EDGE_EVENT_ACTIVE;
		trigger->event_count++;

		LOG_INF("Event count: %d", trigger->event_count);
	} else {
		LOG_WRN("Measurement full");
		app_data_unlock();
		return;
	}

	trigger->trigger_active = edge_event == CTR_EDGE_EVENT_ACTIVE;

	LOG_INF("Input: %d", (int)trigger->trigger_active);

	if (g_app_config.trigger_report_active && edge_event == CTR_EDGE_EVENT_ACTIVE) {
		send_with_rate_limit();
	}

	if (g_app_config.trigger_report_inactive && edge_event == CTR_EDGE_EVENT_INACTIVE) {
		send_with_rate_limit();
	}

	app_data_unlock();
}

void app_handler_edge_counter_callback(struct ctr_edge *edge, enum ctr_edge_event edge_event,
				       void *user_data)
{
	if (edge_event == CTR_EDGE_EVENT_ACTIVE) {
		app_data_lock();

		g_app_data.counter.value++;
		g_app_data.counter.delta++;
		LOG_INF("Counter: %llu", g_app_data.counter.value);

		app_data_unlock();
	}
}

#endif /* defined(CONFIG_SHIELD_CTR_X0_A) */

#if defined(CONFIG_SHIELD_CTR_Z)

void app_handler_ctr_z(const struct device *dev, enum ctr_z_event backup_event, void *param)
{
	int ret;

	if (backup_event != CTR_Z_EVENT_DC_CONNECTED &&
	    backup_event != CTR_Z_EVENT_DC_DISCONNECTED) {
		return;
	}

	struct app_data_backup *backup = &g_app_data.backup;

	app_work_backup_update();

	app_data_lock();

	backup->line_present = backup_event == CTR_Z_EVENT_DC_CONNECTED;

	if (backup->event_count < APP_DATA_MAX_BACKUP_EVENTS) {
		struct app_data_backup_event *event = &backup->events[backup->event_count];

		ret = ctr_rtc_get_ts(&event->timestamp);
		if (ret) {
			LOG_ERR("Call `ctr_rtc_get_ts` failed: %d", ret);
			app_data_unlock();
			return;
		}

		event->connected = backup->line_present;
		backup->event_count++;

		LOG_INF("Event count: %d", backup->event_count);
	} else {
		LOG_WRN("Measurement full");
		app_data_unlock();
		return;
	}

	LOG_INF("Backup: %d", (int)backup->line_present);

	if (g_app_config.backup_report_connected && backup_event == CTR_Z_EVENT_DC_CONNECTED) {
		send_with_rate_limit();
	}

	if (g_app_config.backup_report_disconnected &&
	    backup_event == CTR_Z_EVENT_DC_DISCONNECTED) {
		send_with_rate_limit();
	}

	app_data_unlock();
}

#endif /* defined(CONFIG_SHIELD_CTR_Z) */
```

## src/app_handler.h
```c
/*
 * Copyright (c) 2023 HARDWARIO a.s.
 *
 * SPDX-License-Identifier: LicenseRef-HARDWARIO-5-Clause
 */

#ifndef APP_HANDLER_H_
#define APP_HANDLER_H_

/* CHESTER includes */
#include <chester/ctr_edge.h>
#include <chester/ctr_lte.h>
#include <chester/drivers/ctr_z.h>

#ifdef __cplusplus
extern "C" {
#endif

#if defined(CONFIG_SHIELD_CTR_LTE)
void app_handler_lte(enum ctr_lte_event event, union ctr_lte_event_data *data, void *param);
#endif /* defined(CONFIG_SHIELD_CTR_LTE) */

#if defined(CONFIG_SHIELD_CTR_X0_A)
void app_handler_edge_trigger_callback(struct ctr_edge *edge, enum ctr_edge_event edge_event,
				       void *user_data);
void app_handler_edge_counter_callback(struct ctr_edge *edge, enum ctr_edge_event edge_event,
				       void *user_data);
#endif /* defined(CONFIG_SHIELD_CTR_S1) */

#if defined(CONFIG_SHIELD_CTR_Z)
void app_handler_ctr_z(const struct device *dev, enum ctr_z_event event, void *param);
#endif /* defined(CONFIG_SHIELD_CTR_Z) */

#ifdef __cplusplus
}
#endif

#endif /* APP_HANDLER_H_ */
```

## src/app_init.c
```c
/*
 * Copyright (c) 2023 HARDWARIO a.s.
 *
 * SPDX-License-Identifier: LicenseRef-HARDWARIO-5-Clause
 */

#include "app_config.h"
#include "app_data.h"
#include "app_handler.h"
#include "app_init.h"
#include "app_work.h"

/* CHESTER includes */
#include <chester/ctr_adc.h>
#include <chester/ctr_button.h>
#include <chester/ctr_ds18b20.h>
#include <chester/ctr_edge.h>
#include <chester/ctr_led.h>
#include <chester/ctr_lte.h>
#include <chester/ctr_wdog.h>
#include <chester/drivers/ctr_x0.h>
#include <chester/drivers/ctr_z.h>

/* Zephyr includes */
#include <zephyr/device.h>
#include <zephyr/devicetree.h>
#include <zephyr/drivers/gpio.h>
#include <zephyr/kernel.h>
#include <zephyr/logging/log.h>
#include <zephyr/sys/byteorder.h>

/* Standard includes */
#include <errno.h>
#include <math.h>
#include <stddef.h>
#include <stdint.h>

LOG_MODULE_REGISTER(app_init, LOG_LEVEL_DBG);

#if defined(CONFIG_SHIELD_CTR_LTE)
K_SEM_DEFINE(g_app_init_sem, 0, 1);
#endif /* defined(CONFIG_SHIELD_CTR_LTE) */

struct ctr_wdog_channel g_app_wdog_channel;

#if defined(CONFIG_SHIELD_CTR_Z)

static int init_chester_z(void)
{
	int ret;

	static const struct device *dev = DEVICE_DT_GET(DT_NODELABEL(ctr_z));

	if (!device_is_ready(dev)) {
		LOG_ERR("Device not ready");
		return -ENODEV;
	}

	ret = ctr_z_set_handler(dev, app_handler_ctr_z, NULL);
	if (ret) {
		LOG_ERR("Call `ctr_z_set_handler` failed: %d", ret);
		return ret;
	}

	ret = ctr_z_enable_interrupts(dev);
	if (ret) {
		LOG_ERR("Call `ctr_z_enable_interrupts` failed: %d", ret);
		return ret;
	}

	uint32_t serial_number;
	ret = ctr_z_get_serial_number(dev, &serial_number);
	if (ret) {
		LOG_ERR("Call `ctr_z_get_serial_number` failed: %d", ret);
		return ret;
	}

	LOG_INF("Serial number: %08x", serial_number);

	uint16_t hw_revision;
	ret = ctr_z_get_hw_revision(dev, &hw_revision);
	if (ret) {
		LOG_ERR("Call `ctr_z_get_hw_revision` failed: %d", ret);
		return ret;
	}

	LOG_INF("HW revision: %04x", hw_revision);

	uint32_t hw_variant;
	ret = ctr_z_get_hw_variant(dev, &hw_variant);
	if (ret) {
		LOG_ERR("Call `ctr_z_get_hw_variant` failed: %d", ret);
		return ret;
	}

	LOG_INF("HW variant: %08x", hw_variant);

	uint32_t fw_version;
	ret = ctr_z_get_fw_version(dev, &fw_version);
	if (ret) {
		LOG_ERR("Call `ctr_z_get_fw_version` failed: %d", ret);
		return ret;
	}

	LOG_INF("FW version: %08x", fw_version);

	char vendor_name[32];
	ret = ctr_z_get_vendor_name(dev, vendor_name, sizeof(vendor_name));
	if (ret) {
		LOG_ERR("Call `ctr_z_get_vendor_name` failed: %d", ret);
		return ret;
	}

	LOG_INF("Vendor name: %s", vendor_name);

	char product_name[32];
	ret = ctr_z_get_product_name(dev, product_name, sizeof(product_name));
	if (ret) {
		LOG_ERR("Call `ctr_z_get_product_name` failed: %d", ret);
		return ret;
	}

	LOG_INF("Product name: %s", product_name);

	return 0;
}

#endif /* defined(CONFIG_SHIELD_CTR_Z) */

#if defined(CONFIG_SHIELD_CTR_X0_A)

static int init_edge(struct ctr_edge *edge, ctr_edge_cb_t cb, const struct device *dev,
		     enum ctr_x0_channel channel, enum ctr_x0_mode mode, int active_duration,
		     int inactive_duration, int cooldown_time)
{
	int ret;

	/* Call ctr_x0_set_mode only in NPN mode. In PNP we will use MCU internal pull-down to get
	 * lower analog threshold for GPIO interrupt (21 V vs 15.5 V) */
	if (mode == CTR_X0_MODE_NPN_INPUT) {
		ret = ctr_x0_set_mode(dev, channel, mode);
		if (ret) {
			LOG_ERR("Call `ctr_x0_set_mode` failed: %d", ret);
			return ret;
		}
	}

	const struct gpio_dt_spec *spec;
	ret = ctr_x0_get_spec(dev, channel, &spec);
	if (ret) {
		LOG_ERR("Call `ctr_x0_get_spec` failed: %d", ret);
		return ret;
	}

	if (mode == CTR_X0_MODE_NPN_INPUT) {
		ret = gpio_pin_configure_dt(spec, GPIO_INPUT | GPIO_ACTIVE_LOW);
		if (ret) {
			LOG_ERR("Call `gpio_pin_configure_dt` failed: %d", ret);
			return ret;
		}
	} else {
		/* Apply pull-down on MCU instead of X0 to get lower analog threshold for GPIO
		 * interrupt */
		ret = gpio_pin_configure_dt(spec, GPIO_INPUT | GPIO_ACTIVE_HIGH | GPIO_PULL_DOWN);
		if (ret) {
			LOG_ERR("Call `gpio_pin_configure_dt` failed: %d", ret);
			return ret;
		}
	}

	ret = ctr_edge_init(edge, spec, false);
	if (ret) {
		LOG_ERR("Call `ctr_edge_init` failed: %d", ret);
		return ret;
	}

	ret = ctr_edge_set_callback(edge, cb, NULL);
	if (ret) {
		LOG_ERR("Call `ctr_edge_set_callback` failed: %d", ret);
		return ret;
	}

	ret = ctr_edge_set_cooldown_time(edge, cooldown_time);
	if (ret) {
		LOG_ERR("Call `ctr_edge_set_cooldown_time` failed: %d", ret);
		return ret;
	}

	ret = ctr_edge_set_active_duration(edge, active_duration);
	if (ret) {
		LOG_ERR("Call `ctr_edge_set_active_duration` failed: %d", ret);
		return ret;
	}

	ret = ctr_edge_set_inactive_duration(edge, inactive_duration);
	if (ret) {
		LOG_ERR("Call `ctr_edge_set_inactive_duration` failed: %d", ret);
		return ret;
	}

	ret = ctr_edge_watch(edge);
	if (ret) {
		LOG_ERR("Call `ctr_edge_watch` failed: %d", ret);
		return ret;
	}

	return 0;
}

static int init_chester_x0(void)
{
	int ret;

	static const struct device *dev = DEVICE_DT_GET(DT_NODELABEL(ctr_x0_a));

	if (!device_is_ready(dev)) {
		LOG_ERR("Device not ready");
		return -ENODEV;
	}

	if (g_app_config.trigger_input_type != APP_CONFIG_INPUT_TYPE_NPN &&
	    g_app_config.trigger_input_type != APP_CONFIG_INPUT_TYPE_PNP) {
		LOG_ERR("Unknown trigger input type");
		return -EINVAL;
	}

	enum ctr_x0_mode trigger_mode = g_app_config.trigger_input_type == APP_CONFIG_INPUT_TYPE_NPN
						? CTR_X0_MODE_NPN_INPUT
						: CTR_X0_MODE_PNP_INPUT;

	/* Channel 1: Trigger input */
	static struct ctr_edge edge_trigger;
	ret = init_edge(&edge_trigger, app_handler_edge_trigger_callback, dev, CTR_X0_CHANNEL_1,
			trigger_mode, g_app_config.trigger_duration_active,
			g_app_config.trigger_duration_inactive, g_app_config.trigger_cooldown_time);
	if (ret) {
		LOG_ERR("Call `init_edge` failed: %d", ret);
		return ret;
	}

	if (g_app_config.counter_input_type != APP_CONFIG_INPUT_TYPE_NPN &&
	    g_app_config.counter_input_type != APP_CONFIG_INPUT_TYPE_PNP) {
		LOG_ERR("Unknown counter input type");
		return -EINVAL;
	}

	enum ctr_x0_mode counter_mode = g_app_config.counter_input_type == APP_CONFIG_INPUT_TYPE_NPN
						? CTR_X0_MODE_NPN_INPUT
						: CTR_X0_MODE_PNP_INPUT;

	/* Channel 2: Counter input */
	static struct ctr_edge edge_counter;
	ret = init_edge(&edge_counter, app_handler_edge_counter_callback, dev, CTR_X0_CHANNEL_2,
			counter_mode, g_app_config.counter_duration_active,
			g_app_config.counter_duration_inactive, g_app_config.counter_cooldown_time);
	if (ret) {
		LOG_ERR("Call `init_edge` failed: %d", ret);
		return ret;
	}

	/* Channel 3: Analog voltage input (0-10 V) */
	ret = ctr_x0_set_mode(dev, CTR_X0_CHANNEL_3, CTR_X0_MODE_AI_INPUT);
	if (ret) {
		LOG_ERR("Call `ctr_x0_set_mode` failed: %d", ret);
		return ret;
	}

	ret = ctr_adc_init(CTR_ADC_CHANNEL_A2);
	if (ret) {
		LOG_ERR("Call `ctr_adc_init` failed: %d", ret);
		k_oops();
	}

	/* Channel 4: Current loop input (4-20 mA) */
	ret = ctr_x0_set_mode(dev, CTR_X0_CHANNEL_4, CTR_X0_MODE_CL_INPUT);
	if (ret) {
		LOG_ERR("Call `ctr_x0_set_mode` failed: %d", ret);
		return ret;
	}

	ret = ctr_adc_init(CTR_ADC_CHANNEL_A3);
	if (ret) {
		LOG_ERR("Call `ctr_adc_init` failed: %d", ret);
		k_oops();
	}

	return 0;
}

#endif /* defined(CONFIG_SHIELD_CTR_X0_A) */

int app_init(void)
{
	int ret;

	ctr_led_set(CTR_LED_CHANNEL_R, true);

	ret = ctr_wdog_set_timeout(120000);
	if (ret) {
		LOG_ERR("Call `ctr_wdog_set_timeout` failed: %d", ret);
		return ret;
	}

	ret = ctr_wdog_install(&g_app_wdog_channel);
	if (ret) {
		LOG_ERR("Call `ctr_wdog_install` failed: %d", ret);
		return ret;
	}

	ret = ctr_wdog_start();
	if (ret) {
		LOG_ERR("Call `ctr_wdog_start` failed: %d", ret);
		return ret;
	}

#if defined(CONFIG_CTR_BUTTON)
	ret = ctr_button_set_event_cb(app_handler_ctr_button, NULL);
	if (ret) {
		LOG_ERR("Call `ctr_button_set_event_cb` failed: %d", ret);
		return ret;
	}
#endif /* defined(CONFIG_CTR_BUTTON) */

#if defined(CONFIG_SHIELD_CTR_LTE)
	ret = ctr_lte_set_event_cb(app_handler_lte, NULL);
	if (ret) {
		LOG_ERR("Call `ctr_lte_set_event_cb` failed: %d", ret);
		return ret;
	}

	ret = ctr_lte_start(NULL);
	if (ret) {
		LOG_ERR("Call `ctr_lte_start` failed: %d", ret);
		return ret;
	}

	for (;;) {
		ret = ctr_wdog_feed(&g_app_wdog_channel);
		if (ret) {
			LOG_ERR("Call `ctr_wdog_feed` failed: %d", ret);
			return ret;
		}

		ret = k_sem_take(&g_app_init_sem, K_SECONDS(1));
		if (ret == -EAGAIN) {
			continue;
		} else if (ret) {
			LOG_ERR("Call `k_sem_take` failed: %d", ret);
			return ret;
		}

		break;
	}
#endif /* defined(CONFIG_SHIELD_CTR_LTE) */

	ctr_led_set(CTR_LED_CHANNEL_R, false);

	ret = app_work_init();
	if (ret) {
		LOG_ERR("Call `app_work_init` failed: %d", ret);
		return ret;
	}

#if defined(CONFIG_SHIELD_CTR_Z)
	ret = init_chester_z();
	if (ret) {
		LOG_ERR("Call `init_chester_z` failed: %d", ret);
		return ret;
	}
#endif /* defined(CONFIG_SHIELD_CTR_Z) */

#if defined(CONFIG_SHIELD_CTR_X0_A)
	ret = init_chester_x0();
	if (ret) {
		LOG_ERR("Call `init_chester_x0` failed: %d", ret);
		k_oops();
	}
#endif /* defined(CONFIG_SHIELD_CTR_X0_A) */

#if defined(CONFIG_SHIELD_CTR_DS18B20)
	ret = ctr_ds18b20_scan();
	if (ret) {
		LOG_ERR("Call `ctr_ds18b20_scan` failed: %d", ret);
		return ret;
	}
#endif /* defined(CONFIG_SHIELD_CTR_DS18B20) */

	return 0;
}
```

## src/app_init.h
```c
#ifndef APP_INIT_H_
#define APP_INIT_H_

/* Zephyr includes */
#include <zephyr/zephyr.h>

#ifdef __cplusplus
extern "C" {
#endif

extern struct k_sem g_app_init_sem;

int app_init(void);

#ifdef __cplusplus
}
#endif

#endif /* APP_INIT_H_ */
```

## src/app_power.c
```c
#include "app_data.h"
#include "app_power.h"

/* CHESTER includes */
#include <chester/drivers/ctr_batt.h>

/* Zephyr includes */
#include <zephyr/device.h>
#include <zephyr/devicetree.h>
#include <zephyr/kernel.h>
#include <zephyr/logging/log.h>

/* Standard includes */
#include <errno.h>
#include <math.h>

LOG_MODULE_REGISTER(app_power, LOG_LEVEL_DBG);

int app_power_sample(void)
{
	int ret;

	static const struct device *dev = DEVICE_DT_GET(DT_NODELABEL(ctr_batt));

	if (!device_is_ready(dev)) {
		LOG_ERR("Device not ready");
		ret = -ENODEV;
		goto error;
	}

	int rest_mv;
	ret = ctr_batt_get_rest_voltage_mv(dev, &rest_mv, CTR_BATT_REST_TIMEOUT_DEFAULT_MS);
	if (ret) {
		LOG_ERR("Call `ctr_batt_get_rest_voltage_mv` failed: %d", ret);
		goto error;
	}

	int load_mv;
	ret = ctr_batt_get_load_voltage_mv(dev, &load_mv, CTR_BATT_LOAD_TIMEOUT_DEFAULT_MS);
	if (ret) {
		LOG_ERR("Call `ctr_batt_get_load_voltage_mv` failed: %d", ret);
		goto error;
	}

	int current_ma;
	ctr_batt_get_load_current_ma(dev, &current_ma, load_mv);

	LOG_INF("Battery voltage (rest): %d mV", rest_mv);
	LOG_INF("Battery voltage (load): %d mV", load_mv);
	LOG_INF("Battery current (load): %d mA", current_ma);

	app_data_lock();

	g_app_data.system_voltage_rest = rest_mv;
	g_app_data.system_voltage_load = load_mv;
	g_app_data.system_current_load = current_ma;

	app_data_unlock();

	return 0;

error:
	app_data_lock();

	g_app_data.system_voltage_rest = NAN;
	g_app_data.system_voltage_load = NAN;
	g_app_data.system_current_load = NAN;

	app_data_unlock();

	return ret;
}
```
